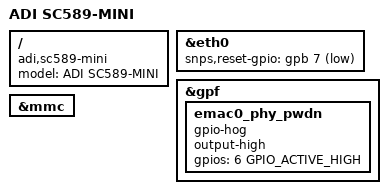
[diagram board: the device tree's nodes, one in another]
// SPDX-License-Identifier: GPL-2.0-or-later
/*
 * (C) Copyright 2024 - Analog Devices, Inc.
 */

/dts-v1/;

#include "sc58x.dtsi"

/ {
	model = "ADI SC589-MINI";
	compatible = "adi,sc589-mini", "adi,sc58x";
};

&eth0 {
	snps,reset-gpio = <&gpb 7 GPIO_ACTIVE_LOW>;
};

&gpf {
	emac0_phy_pwdn {
		gpio-hog;
		output-high;
		gpios = <6 GPIO_ACTIVE_HIGH>;
	};
};

&mmc {
	status = "okay";
};
